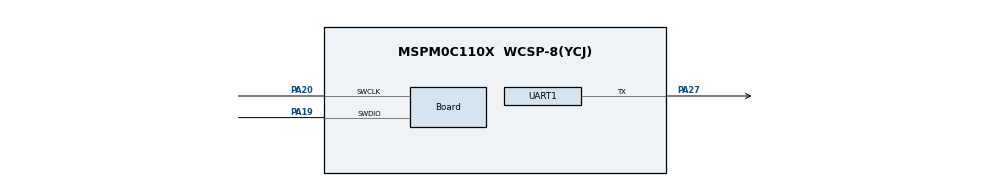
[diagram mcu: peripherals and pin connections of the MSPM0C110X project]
/**
 * @cliArgs --device "MSPM0C110X" --part "Default" --package "WCSP-8(YCJ)" --product "mspm0_sdk@2.04.00.06"
 * @versions {"tool":"1.23.0+4000"}
 */

/**
 * Import the modules used in this configuration.
 */
const ADC12  = scripting.addModule("/ti/driverlib/ADC12", {}, false);
const ADC121 = ADC12.addInstance();
const Board  = scripting.addModule("/ti/driverlib/Board");
const PWM    = scripting.addModule("/ti/driverlib/PWM", {}, false);
const PWM1   = PWM.addInstance();
const SYSCTL = scripting.addModule("/ti/driverlib/SYSCTL");
const UART   = scripting.addModule("/ti/driverlib/UART", {}, false);
const UART1  = UART.addInstance();
const VREF   = scripting.addModule("/ti/driverlib/VREF");

/**
 * Write custom configuration values to the imported modules.
 */
ADC121.$name                 = "ADC12_0";
ADC121.sampClkDiv            = "DL_ADC12_CLOCK_DIVIDE_8";
ADC121.adcMem0chansel        = "DL_ADC12_INPUT_CHAN_2";
ADC121.adcMem1chansel        = "DL_ADC12_INPUT_CHAN_3";
ADC121.adcMem3chansel        = "DL_ADC12_INPUT_CHAN_7";
ADC121.enabledInterrupts     = ["DL_ADC12_INTERRUPT_DMA_DONE","DL_ADC12_INTERRUPT_MEM0_RESULT_LOADED","DL_ADC12_INTERRUPT_MEM1_RESULT_LOADED","DL_ADC12_INTERRUPT_MEM2_RESULT_LOADED","DL_ADC12_INTERRUPT_MEM3_RESULT_LOADED","DL_ADC12_INTERRUPT_OVERFLOW","DL_ADC12_INTERRUPT_TRIG_OVF","DL_ADC12_INTERRUPT_UNDERFLOW"];
ADC121.adcMem2chansel        = "DL_ADC12_INPUT_CHAN_5";
ADC121.samplingOperationMode = "sequence";
ADC121.startAdd              = 1;
ADC121.endAdd                = 1;
ADC121.adcPin3Config.$name   = "ti_driverlib_gpio_GPIOPinGeneric0";

Board.configureVDDA               = true;
Board.peripheral.$assign          = "DEBUGSS";
Board.peripheral.swclkPin.$assign = "PA20";
Board.peripheral.swdioPin.$assign = "PA19";

PWM1.$name               = "PWM_0";
PWM1.timerStartTimer     = true;
PWM1.pwmMode             = "EDGE_ALIGN_UP";
PWM1.timerCount          = 255;
PWM1.ccIndex             = [0];
PWM1.PWM_CHANNEL_0.$name = "ti_driverlib_pwm_PWMTimerCC0";
PWM1.ccp0PinConfig.$name = "ti_driverlib_gpio_GPIOPinGeneric1";
PWM1.peripheral.$assign  = "TIMG8";

SYSCTL.peripheral.$assign = "SYSCTL";

UART1.$name                    = "UART_0";
UART1.targetBaudRate           = 115200;
UART1.direction                = "TX";
UART1.txPinConfig.$name        = "ti_driverlib_gpio_GPIOPinGeneric4";
UART1.peripheral.$assign       = "UART0";
UART1.peripheral.txPin.$assign = "PA27";

const ProjectConfig              = scripting.addModule("/ti/project_config/ProjectConfig", {}, false);
ProjectConfig.migrationCondition = true;

/**
 * Pinmux solution for unlocked pins/peripherals. This ensures that minor changes to the automatic solver in a future
 * version of the tool will not impact the pinmux you originally saw.  These lines can be completely deleted in order to
 * re-solve from scratch.
 */
ADC121.peripheral.$suggestSolution         = "ADC0";
ADC121.peripheral.adcPin3.$suggestSolution = "PA24";
PWM1.peripheral.ccp0Pin.$suggestSolution   = "PA0";
